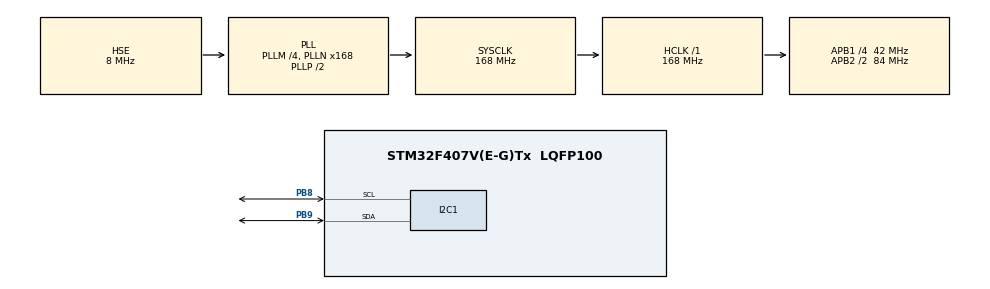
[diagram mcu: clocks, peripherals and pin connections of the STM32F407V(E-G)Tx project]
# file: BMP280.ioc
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I2C1.I2C_Mode=I2C_Fast
Mcu.Family=STM32F4
Mcu.Name=STM32F407V(E-G)Tx
Mcu.Package=LQFP100
NVIC.PriorityGroup=NVIC_PRIORITYGROUP_4
PA13.Mode=Trace_Asynchronous_SW
PA13.Signal=SYS_JTMS-SWDIO
PA14.Mode=Trace_Asynchronous_SW
PA14.Signal=SYS_JTCK-SWCLK
PB3.Mode=Trace_Asynchronous_SW
PB3.Signal=SYS_JTDO-SWO
PB8.Mode=I2C
PB8.Signal=I2C1_SCL
PB9.Mode=I2C
PB9.Signal=I2C1_SDA
PH0-OSC_IN.Mode=HSE-External-Oscillator
PH0-OSC_IN.Signal=RCC_OSC_IN
PH1-OSC_OUT.Mode=HSE-External-Oscillator
PH1-OSC_OUT.Signal=RCC_OSC_OUT
ProjectManager.HeapSize=0x200
ProjectManager.StackSize=0x400
ProjectManager.TargetToolchain=EWARM
RCC.48MHZClocksFreq_Value=84000000
RCC.AHBFreq_Value=168000000
RCC.APB1CLKDivider=RCC_HCLK_DIV4
RCC.APB1Freq_Value=42000000
RCC.APB1TimFreq_Value=84000000
RCC.APB2CLKDivider=RCC_HCLK_DIV2
RCC.APB2Freq_Value=84000000
RCC.APB2TimFreq_Value=168000000
RCC.CortexFreq_Value=168000000
RCC.HCLKFreq_Value=168000000
RCC.HSE_VALUE=8000000
RCC.HSI_VALUE=16000000
RCC.LSE_VALUE=32768
RCC.PLLM=4
RCC.PLLN=168
RCC.PLLSourceVirtual=RCC_PLLSOURCE_HSE
RCC.SYSCLKFreq_VALUE=168000000
RCC.SYSCLKSource=RCC_SYSCLKSOURCE_PLLCLK
RCC.VCOOutputFreq_Value=336000000
board=BMP280

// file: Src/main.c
/**
  ******************************************************************************
  * File Name          : main.c
  * Description        : Main program body
  ******************************************************************************
  *
  * COPYRIGHT(c) 2016 STMicroelectronics
  *
  * Redistribution and use in source and binary forms, with or without modification,
  * are permitted provided that the following conditions are met:
  *   1. Redistributions of source code must retain the above copyright notice,
  *      this list of conditions and the following disclaimer.
  *   2. Redistributions in binary form must reproduce the above copyright notice,
  *      this list of conditions and the following disclaimer in the documentation
  *      and/or other materials provided with the distribution.
  *   3. Neither the name of STMicroelectronics nor the names of its contributors
  *      may be used to endorse or promote products derived from this software
  *      without specific prior written permission.
  *
  * THIS SOFTWARE IS PROVIDED BY THE COPYRIGHT HOLDERS AND CONTRIBUTORS "AS IS"
  * AND ANY EXPRESS OR IMPLIED WARRANTIES, INCLUDING, BUT NOT LIMITED TO, THE
  * IMPLIED WARRANTIES OF MERCHANTABILITY AND FITNESS FOR A PARTICULAR PURPOSE ARE
  * DISCLAIMED. IN NO EVENT SHALL THE COPYRIGHT HOLDER OR CONTRIBUTORS BE LIABLE
  * FOR ANY DIRECT, INDIRECT, INCIDENTAL, SPECIAL, EXEMPLARY, OR CONSEQUENTIAL
  * DAMAGES (INCLUDING, BUT NOT LIMITED TO, PROCUREMENT OF SUBSTITUTE GOODS OR
  * SERVICES; LOSS OF USE, DATA, OR PROFITS; OR BUSINESS INTERRUPTION) HOWEVER
  * CAUSED AND ON ANY THEORY OF LIABILITY, WHETHER IN CONTRACT, STRICT LIABILITY,
  * OR TORT (INCLUDING NEGLIGENCE OR OTHERWISE) ARISING IN ANY WAY OUT OF THE USE
  * OF THIS SOFTWARE, EVEN IF ADVISED OF THE POSSIBILITY OF SUCH DAMAGE.
  *
  ******************************************************************************
  */
#include "main.h"
#include "stm32f4xx_hal.h"

/* USER CODE BEGIN Includes */
#include "bmp280.h"
#include <stdio.h>
#include <math.h>
/* USER CODE END Includes */

I2C_HandleTypeDef hi2c1;

/* USER CODE BEGIN PV */
/* Private variables ---------------------------------------------------------*/
struct bmp280_t bmp280;
/* USER CODE END PV */

void SystemClock_Config(void);
void Error_Handler(void);
static void MX_GPIO_Init(void);
static void MX_I2C1_Init(void);

/* USER CODE BEGIN PFP */
/* Private function prototypes -----------------------------------------------*/

/* USER CODE END PFP */

/* USER CODE BEGIN 0 */
s8  BMP280_I2C_bus_write(u8 dev_addr, u8 reg_addr, u8 *reg_data, u8 cnt)
{
	if(HAL_I2C_Mem_Write(&hi2c1, dev_addr, reg_addr, I2C_MEMADD_SIZE_8BIT, reg_data, cnt, 2) == HAL_OK)
		return BMP280_INIT_VALUE;
	else
		return -1;
}

s8  BMP280_I2C_bus_read(u8 dev_addr, u8 reg_addr, u8 *reg_data, u8 cnt)
{
	if(HAL_I2C_Mem_Read(&hi2c1, dev_addr, reg_addr, I2C_MEMADD_SIZE_8BIT, reg_data, cnt, 2) == HAL_OK)
		return BMP280_INIT_VALUE;
	else
		return -1;
}

s32 bmp280_data_readout_template(void)
{
	/* The variable used to assign the standby time*/
	u8 v_standby_time_u8 = BMP280_INIT_VALUE;

	/* The variables used in individual data read APIs*/
	/* The variable used to read uncompensated temperature*/
	s32 v_data_uncomp_tem_s32 = BMP280_INIT_VALUE;
	/* The variable used to read uncompensated pressure*/
	s32 v_data_uncomp_pres_s32 = BMP280_INIT_VALUE;
	/* The variable used to read real temperature*/
	s32 v_actual_temp_s32 = BMP280_INIT_VALUE;
	/* The variable used to read real pressure*/
	u32 v_actual_press_u32 = BMP280_INIT_VALUE;

	/* The variables used in combined data read APIs*/
	/* The variable used to read uncompensated temperature*/
	s32 v_data_uncomp_tem_combined_s32 = BMP280_INIT_VALUE;
	/* The variable used to read uncompensated pressure*/
	s32 v_data_uncomp_pres_combined_s32 = BMP280_INIT_VALUE;
	/* The variable used to read real temperature*/
	s32 v_actual_temp_combined_s32 = BMP280_INIT_VALUE;
	/* The variable used to read real pressure*/
	u32 v_actual_press_combined_u32 = BMP280_INIT_VALUE;

	/* result of communication results*/
	s32 com_rslt = ERROR;
/*********************** START INITIALIZATION ************************/
  /*	Based on the user need configure I2C or SPI interface.
   *	It is example code to explain how to use the bmp280 API*/
	bmp280.bus_write = BMP280_I2C_bus_write;
	bmp280.bus_read = BMP280_I2C_bus_read;
	bmp280.dev_addr = BMP280_I2C_ADDRESS1 << 1;
	bmp280.delay_msec = HAL_Delay;
/*--------------------------------------------------------------------------*
 *  This function used to assign the value/reference of
 *	the following parameters
 *	I2C address
 *	Bus Write
 *	Bus read
 *	Chip id
*-------------------------------------------------------------------------*/
	com_rslt = bmp280_init(&bmp280);

	/*	For initialization it is required to set the mode of
	 *	the sensor as "NORMAL"
	 *	data acquisition/read/write is possible in this mode
	 *	by using the below API able to set the power mode as NORMAL*/
	/* Set the power mode as NORMAL*/
	com_rslt += bmp280_set_power_mode(BMP280_NORMAL_MODE);
	/*	For reading the pressure and temperature data it is required to
	 *	set the work mode
	 *	The measurement period in the Normal mode is depends on the setting of
	 *	over sampling setting of pressure, temperature and standby time
	 *
	 *	OSS				pressure OSS	temperature OSS
	 *	ultra low power			x1			x1
	 *	low power			x2			x1
	 *	standard resolution		x4			x1
	 *	high resolution			x8			x2
	 *	ultra high resolution		x16			x2
	 */
	/* The oversampling settings are set by using the following API*/
	com_rslt += bmp280_set_work_mode(BMP280_ULTRA_LOW_POWER_MODE);
/*------------------------------------------------------------------------*
************************* START GET and SET FUNCTIONS DATA ****************
*---------------------------------------------------------------------------*/
	/* This API used to Write the standby time of the sensor input
	 *	value have to be given*/
	 /*	Normal mode comprises an automated perpetual cycling between an (active)
	 *	Measurement period and an (inactive) standby period.
	 *	The standby time is determined by the contents of the register t_sb.
	 *	Standby time can be set using BMP280_STANDBYTIME_125_MS.
	 *	Usage Hint : BMP280_set_standbydur(BMP280_STANDBYTIME_125_MS)*/

	com_rslt += bmp280_set_standby_durn(BMP280_STANDBY_TIME_1_MS);

	/* This API used to read back the written value of standby time*/
	com_rslt += bmp280_get_standby_durn(&v_standby_time_u8);
/*-----------------------------------------------------------------*
************************* END GET and SET FUNCTIONS ****************
*------------------------------------------------------------------*/

/************************* END INITIALIZATION *************************/

/*------------------------------------------------------------------*
****** INDIVIDUAL APIs TO READ UNCOMPENSATED PRESSURE AND TEMPERATURE*******
*---------------------------------------------------------------------*/
	/* API is used to read the uncompensated temperature*/
	com_rslt += bmp280_read_uncomp_temperature(&v_data_uncomp_tem_s32);

	/* API is used to read the uncompensated pressure*/
	com_rslt += bmp280_read_uncomp_pressure(&v_data_uncomp_pres_s32);

	/* API is used to read the true temperature*/
	/* Input value as uncompensated temperature*/
	v_actual_temp_s32 = bmp280_compensate_temperature_int32(v_data_uncomp_tem_s32);

	/* API is used to read the true pressure*/
	/* Input value as uncompensated pressure*/
	v_actual_press_u32 = bmp280_compensate_pressure_int32(v_data_uncomp_pres_s32);

/*------------------------------------------------------------------*
******* STAND-ALONE APIs TO READ COMBINED TRUE PRESSURE AND TEMPERATURE********
*---------------------------------------------------------------------*/

	/* API is used to read the uncompensated temperature and pressure*/
	com_rslt += bmp280_read_uncomp_pressure_temperature(&v_data_uncomp_pres_combined_s32,
	&v_data_uncomp_tem_combined_s32);

	/* API is used to read the true temperature and pressure*/
	com_rslt += bmp280_read_pressure_temperature(&v_actual_press_combined_u32,
	&v_actual_temp_combined_s32);

	printf("pre:%.3fkPa  temp:%.2fDegC ", v_actual_press_combined_u32 / 1000.0, v_actual_temp_combined_s32 / 100.0);
	float alti;
	alti = 44330 * (1 - pow(v_actual_press_combined_u32 / 101325.0, 1 / 5.255));
	printf("alti:%.2fm\n", alti);

/************************* START DE-INITIALIZATION ***********************/

	/*	For de-initialization it is required to set the mode of
	 *	the sensor as "SLEEP"
	 *	the device reaches the lowest power consumption only
	 *	In SLEEP mode no measurements are performed
	 *	All registers are accessible
	 *	by using the below API able to set the power mode as SLEEP*/
	 /* Set the power mode as SLEEP*/
	com_rslt += bmp280_set_power_mode(BMP280_SLEEP_MODE);

	HAL_Delay(500);

   return com_rslt;
/************************* END DE-INITIALIZATION **********************/
}

/* USER CODE END 0 */

int main(void)
{

  /* MCU Configuration----------------------------------------------------------*/

  /* Reset of all peripherals, Initializes the Flash interface and the Systick. */
  HAL_Init();

  /* Configure the system clock */
  SystemClock_Config();

  /* Initialize all configured peripherals */
  MX_GPIO_Init();
  MX_I2C1_Init();

  /* Infinite loop */
  while (1)
  {

  /* USER CODE BEGIN 3 */
		bmp280_data_readout_template();
  }
  /* USER CODE END 3 */

}

/** System Clock Configuration
*/
void SystemClock_Config(void)
{

  RCC_OscInitTypeDef RCC_OscInitStruct;
  RCC_ClkInitTypeDef RCC_ClkInitStruct;

    /**Configure the main internal regulator output voltage
    */
  __HAL_RCC_PWR_CLK_ENABLE();

  __HAL_PWR_VOLTAGESCALING_CONFIG(PWR_REGULATOR_VOLTAGE_SCALE1);

    /**Initializes the CPU, AHB and APB busses clocks
    */
  RCC_OscInitStruct.OscillatorType = RCC_OSCILLATORTYPE_HSE;
  RCC_OscInitStruct.HSEState = RCC_HSE_ON;
  RCC_OscInitStruct.PLL.PLLState = RCC_PLL_ON;
  RCC_OscInitStruct.PLL.PLLSource = RCC_PLLSOURCE_HSE;
  RCC_OscInitStruct.PLL.PLLM = 4;
  RCC_OscInitStruct.PLL.PLLN = 168;
  RCC_OscInitStruct.PLL.PLLP = RCC_PLLP_DIV2;
  RCC_OscInitStruct.PLL.PLLQ = 4;
  if (HAL_RCC_OscConfig(&RCC_OscInitStruct) != HAL_OK)
  {
    Error_Handler();
  }

    /**Initializes the CPU, AHB and APB busses clocks
    */
  RCC_ClkInitStruct.ClockType = RCC_CLOCKTYPE_HCLK|RCC_CLOCKTYPE_SYSCLK
                              |RCC_CLOCKTYPE_PCLK1|RCC_CLOCKTYPE_PCLK2;
  RCC_ClkInitStruct.SYSCLKSource = RCC_SYSCLKSOURCE_PLLCLK;
  RCC_ClkInitStruct.AHBCLKDivider = RCC_SYSCLK_DIV1;
  RCC_ClkInitStruct.APB1CLKDivider = RCC_HCLK_DIV4;
  RCC_ClkInitStruct.APB2CLKDivider = RCC_HCLK_DIV2;

  if (HAL_RCC_ClockConfig(&RCC_ClkInitStruct, FLASH_LATENCY_5) != HAL_OK)
  {
    Error_Handler();
  }

    /**Configure the Systick interrupt time
    */
  HAL_SYSTICK_Config(HAL_RCC_GetHCLKFreq()/1000);

    /**Configure the Systick
    */
  HAL_SYSTICK_CLKSourceConfig(SYSTICK_CLKSOURCE_HCLK);

  /* SysTick_IRQn interrupt configuration */
  HAL_NVIC_SetPriority(SysTick_IRQn, 0, 0);
}

/* I2C1 init function */
static void MX_I2C1_Init(void)
{

  hi2c1.Instance = I2C1;
  hi2c1.Init.ClockSpeed = 400000;
  hi2c1.Init.DutyCycle = I2C_DUTYCYCLE_2;
  hi2c1.Init.OwnAddress1 = 0;
  hi2c1.Init.AddressingMode = I2C_ADDRESSINGMODE_7BIT;
  hi2c1.Init.DualAddressMode = I2C_DUALADDRESS_DISABLE;
  hi2c1.Init.OwnAddress2 = 0;
  hi2c1.Init.GeneralCallMode = I2C_GENERALCALL_DISABLE;
  hi2c1.Init.NoStretchMode = I2C_NOSTRETCH_DISABLE;
  if (HAL_I2C_Init(&hi2c1) != HAL_OK)
  {
    Error_Handler();
  }

}

/** Configure pins as
        * Analog
        * Input
        * Output
        * EVENT_OUT
        * EXTI
*/
static void MX_GPIO_Init(void)
{

  /* GPIO Ports Clock Enable */
  __HAL_RCC_GPIOH_CLK_ENABLE();
  __HAL_RCC_GPIOA_CLK_ENABLE();
  __HAL_RCC_GPIOB_CLK_ENABLE();

}

void Error_Handler(void)
{
  while(1)
  {
  }
}

/************************ (C) COPYRIGHT STMicroelectronics *****END OF FILE****/
